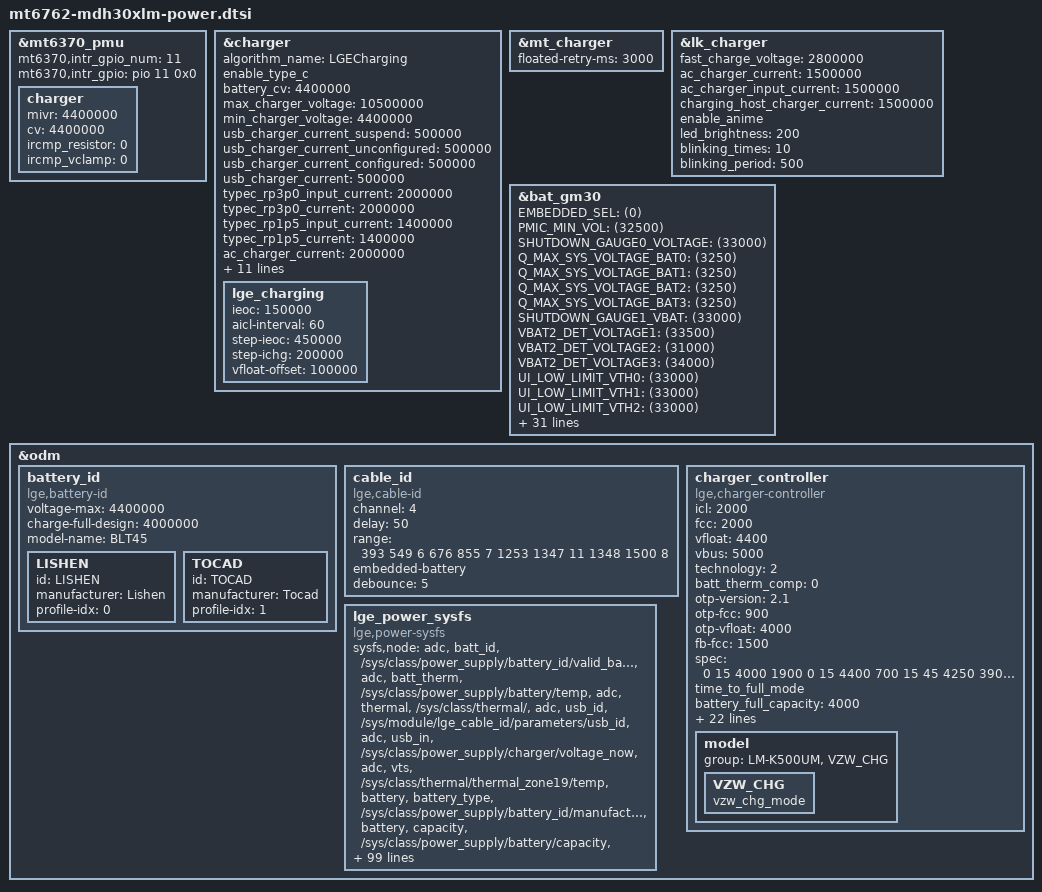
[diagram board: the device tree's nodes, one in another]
/*
 * LG Electronics MT6765 HDK power device tree source
 *
 * Copyright (c) 2018 LG Electronics Co., Ltd.
 *              http://www.lge.com
 *
 */

&mt6370_pmu {
	mt6370,intr_gpio_num = <11>; /* direct defined GPIO num */
	mt6370,intr_gpio = <&pio 11 0x0>;

	charger {
		interrupt-names = "chg_mivr", "chg_aiclmeasi",
			"attachi","ovpctrl_uvp_d_evt", "chg_wdtmri",
			"chg_vbusov","chg_tmri", "chg_treg", "pwr_rdy";
		mivr = <4400000>;	/* uV */
		cv = <4400000>;		/* uA */
		ircmp_resistor = <0>;   /* uohm */
		ircmp_vclamp = <0>;     /* uV */
	};
};

&charger {
	algorithm_name = "LGECharging";

	enable_type_c;

	/* common */
	battery_cv = <4400000>;
	max_charger_voltage = <10500000>;
	min_charger_voltage = <4400000>;

	/* charging current */
	usb_charger_current_suspend = <500000>;
	usb_charger_current_unconfigured = <500000>;
	usb_charger_current_configured = <500000>;
	usb_charger_current = <500000>;
	typec_rp3p0_input_current = <2000000>;
	typec_rp3p0_current = <2000000>;
	typec_rp1p5_input_current = <1400000>;
	typec_rp1p5_current = <1400000>;
	ac_charger_current = <2000000>;
	ac_charger_input_current = <2000000>;
	non_std_ac_charger_current = <500000>;
	charging_host_charger_current = <1500000>;
	apple_1_0a_charger_current = <1000000>;
	apple_2_1a_charger_current = <1000000>;
	ta_ac_charger_current = <2000000>;
	pd_charger_current = <2000000>;

	/* PE 2.0 */
	pe20_ichg_level_threshold = <500000>; /* uA */
	ta_start_battery_soc = <0>;
	ta_stop_battery_soc = <97>;

	/* cable measurement impedance */
	vbat_cable_imp_threshold = <3000000>; /* uV */

	/* LGE Charging Algorithm */
	lge_charging {
		ieoc = <150000>;
		aicl-interval = <60>;

		step-ieoc = <450000>;
		step-ichg = <200000>;
		vfloat-offset = <100000>;
	};
};

&mt_charger {
	floated-retry-ms = <3000>; /* 3000 ms */
};

&lk_charger {
	fast_charge_voltage = <2800000>;
	ac_charger_current = <1500000>;
	ac_charger_input_current = <1500000>;
	charging_host_charger_current = <1500000>;

	enable_anime;
	led_brightness = <200>;
	blinking_times = <10>;
	blinking_period = <500>;
};

&bat_gm30 {
	/*	Configures whether using embedded battery or not.*/
	EMBEDDED_SEL = <(0)>;

	/*
	 * Below setting is cut off 3.3 parameter.
	 * If use cutoff 3.4V, use MTK original parameter
	 */
	/*	vboot voltage for gauge 0%.*/
	PMIC_MIN_VOL = <(32500)>;
	/*	shutdown gauge 0% voltage*/
	SHUTDOWN_GAUGE0_VOLTAGE = <(33000)>;
	/*	System shut down voltage.*/
	Q_MAX_SYS_VOLTAGE_BAT0 = <(3250)>;
	/*	System shut down voltage.*/
	Q_MAX_SYS_VOLTAGE_BAT1 = <(3250)>;
	/*	System shut down voltage.*/
	Q_MAX_SYS_VOLTAGE_BAT2 = <(3250)>;
	/*	System shut down voltage.*/
	Q_MAX_SYS_VOLTAGE_BAT3 = <(3250)>;
	/* no used. Ignore. Just for align with shutdown condition 3.3v */
	SHUTDOWN_GAUGE1_VBAT = <(33000)>;
	/* Related to low voltage tracking */
	VBAT2_DET_VOLTAGE1 = <(33500)>;
	VBAT2_DET_VOLTAGE2 = <(31000)>;
	VBAT2_DET_VOLTAGE3 = <(34000)>;
	/* cut off scenario. below setting means that 2% shutdown with 3.3v. */
	UI_LOW_LIMIT_VTH0 = <(33000)>;
	UI_LOW_LIMIT_VTH1 = <(33000)>;
	UI_LOW_LIMIT_VTH2 = <(33000)>;
	UI_LOW_LIMIT_VTH3 = <(33000)>;
	UI_LOW_LIMIT_VTH4 = <(33000)>;

	g_Q_MAX_SYS_VOLTAGE = <3250 3250 3250 3250>;
	g_PMIC_MIN_VOL = <32500 32500 32500 32500
			32500 32500 32500 32500
			32500 32500 32500 32500
			31200 31200 31200 31200
			30000 30000 30000 30000
			30000 30000 30000 30000
			30000 30000 30000 30000
			30000 30000 30000 30000
			30000 30000 30000 30000
			30000 30000 30000 30000>;

	g_QMAX_SYS_VOL = <32500 32500 32500 32500
			32500 32500 32500 32500
			32500 32500 32500 32500
			31900 31900 31900 31900
			31800 31800 31800 31800
			32500 32500 32500 32500
			32500 32500 32500 32500
			32500 32500 32500 32500
			32500 32500 32500 32500
			32500 32500 32500 32500>;
	/*
	 * Above setting value is cut off 3.3 parameter.
	 * If use cutoff 3.4V, use MTK original parameter
	 */

	/*      Pseudo 100% percentage at T0.*/
	g_FG_PSEUDO100_T0 = <(95)>;
	/*      Pseudo 100% percentage at T1.*/
	g_FG_PSEUDO100_T1 = <(95)>;
	/*      Pseudo 100% percentage at T2.*/
	g_FG_PSEUDO100_T2 = <(95)>;
	/*      Pseudo 100% percentage at T3.*/
	g_FG_PSEUDO100_T3 = <(95)>;

	PSEUDO1_SEL = <(0)>;

	g_FG_PSEUDO1 = <1  1  1  1
			1  1  1  1
			1  1  1  1
			1  1  1  1
			1  1  1  1
			1  1  1  1
			1  1  1  1
			1  1  1  1
			1  1  1  1
			1  1  1  1>;

	DIFFERENCE_FULLOCV_ITH = <(220)>;
	DIFFERENCE_VOLTAGE_UPDATE = <(-1)>;
	AGING1_UPDATE_SOC = <(10)>;
	AGING1_LOAD_SOC = <(50)>;
	AGING_TEMP_DIFF = <(15)>;
	AGING_TEMP_LOW_LIMIT = <(15)>;
	AGING_TEMP_HIGH_LIMIT = <(45)>;
	ZCV_SUSPEND_TIME = <(9)>;
	SLEEP_CURRENT_AVG = <(500)>; /*0.1mA*/

	CAR_TUNE_VALUE = <(100)>;
	HWOCV_OLDOCV_DIFF_CHR = <(2000)>;
	SWOCV_OLDOCV_DIFF_CHR = <(2000)>;
	VIR_OLDOCV_DIFF_EMB = <(2000)>;
	VIR_OLDOCV_DIFF_EMB_LT = <(2000)>;

	POWER_ON_CAR_CHR = <(20)>;
	POWER_ON_CAR_NOCHR = <(-50)>;

	/*The ui_soc will keep 100% until SOC drop X percents after unplugged.*/
	KEEP_100_PERCENT = <(3)>;

#include "../battery_BL-T45.dtsi"
};

&odm {
	/* Battery ID */
	battery_id {
		compatible = "lge,battery-id";

		voltage-max = <4400000>;
		charge-full-design = <4000000>;
		model-name = "BLT45";

		LISHEN {
			id = "LISHEN";
			manufacturer = "Lishen";
			profile-idx = <0>;
		};
		TOCAD {
			id = "TOCAD";
			manufacturer = "Tocad";
			profile-idx = <1>;
		};
	};

	/* Cable ID */
	cable_id {
		compatible = "lge,cable-id";

		channel = <4>;
		delay = <50>;

		/*
		 * Pull-up : 1.8V 150k (1%)
		 * Pull-down : 680k (1%)
		 * ID : 56k (20%), 130k (20%), 910k (20%)
		 * ADC Accuracy : +-10mV
		 */
		range = <
		/*	min 	max 	type	*/
			393	549	6	/* 6: LT_CABLE_56K */
			676	855	7	/* 7: LT_CABLE_130K */
			1253	1347	11	/* 11: LT_CABLE_910K */
			1348	1500	8	/* 8: USB_CABLE_400MA */
		>;

		embedded-battery;
		debounce = <5>;
	};

	/* Charger Controller */
	charger_controller {
		compatible = "lge,charger-controller";

		/* base information */
		icl = <2000>;
		fcc = <2000>;
		vfloat = <4400>;
		vbus = <5000>;
		technology = <2>;
		batt_therm_comp = <0>;

		/* otp */
		otp-version = "2.1";
		otp-fcc = <900>;
		otp-vfloat = <4000>;

		/* restricted charging */
		fb-fcc = <1500>;

		/* spec */
		spec = <
			 0 15 4000 1900	/* 0.5C */
			 0 15 4400  700	/* 0.2C */
			15 45 4250 3900	/* 1.0C */
			15 45 4400 2300	/* 0.6C */
			45 60 4100 1900	/* 0.5C */
		>;

		/* time to full */
		time_to_full_mode;
		battery_full_capacity = <4000>;
		sdp_current = <500>;
		dcp_current = <2000>;
		pep_current = <2200>;
		non_std_current = <500>;
		report_ttf_comp = <0>;
		sdp_comp = <(-2)>;
		dcp_comp = <0>;
		pep_comp = <0>;
		pd_comp = <0>;
		cdp_comp = <0>;
		non_std_comp = <(-2)>;
		min_comp = <0>;
			/*lgc tocad atl byd lishen*/
		batt_comp = <0 (4) 0 0 0>;
			/* current soc */
		cc_data = <2000 0>;
			/* current soc time */
		cv_data = <
			1789	846	1909
			1765	851	1869
			1720	856	1829
			1676	861	1779
			1626	866	1738
			1584	871	1688
			1533	876	1648
			1494	881	1598
			1449	886	1548
			1401	891	1498
			1358	896	1448
			1315	901	1388
			1268	906	1337
			1223	911	1277
			1178	916	1217
			1140	921	1157
			1092	926	1097
			1056	931	1037
			1017	936	966
			970	941	896
			930	946	826
			890	951	756
			851	956	686
			818	961	605
			778	966	525
			743	971	445
			707	977	365
			677	982	265
			638	988	194
			612	991	144
			594	993	94
			577	996	0
			546	1000	0
		>;

		/* game */
		game-fcc = <700>;

		game-light-fcc = <700>;
		game-light-load = <80>;
		game-light-sec = <100>;

		game-lowbatt-fcc = <700>;
		game-lowbatt-soc = <15>;

		/* model */
		model {
			group =
			/* model name, setting */
			"LM-K500UM", "VZW_CHG";

			VZW_CHG {
				/* vzw charge notification */
				vzw_chg_mode;
			};
		};
	};

	/* Unified Power Sysfs */
	lge_power_sysfs {
		compatible = "lge,power-sysfs";
		sysfs,node =
			/* adc group */
			"adc", "batt_id", "/sys/class/power_supply/battery_id/valid_batt_id",
			"adc", "batt_therm", "/sys/class/power_supply/battery/temp",
			"adc", "thermal", "/sys/class/thermal/",
			"adc", "usb_id", "/sys/module/lge_cable_id/parameters/usb_id",
			"adc", "usb_in", "/sys/class/power_supply/charger/voltage_now",
			"adc", "vts", "/sys/class/thermal/thermal_zone19/temp",
			/* battery group */
			"battery", "battery_type", "/sys/class/power_supply/battery_id/manufacturer",
			"battery", "capacity", "/sys/class/power_supply/battery/capacity",
			"battery", "cycle", "/sys/class/power_supply/battery/battery_cycle",
			"battery", "raw_capacity", "/sys/class/power_supply/battery/raw_capacity",
			"battery", "ttf_capacity", "/sys/class/power_supply/battery/ttf_capacity",
			"battery", "health", "/sys/class/power_supply/battery/health",
			"battery", "present", "/sys/class/power_supply/battery/present",
			"battery", "pseudo_batt", "/sys/module/pseudo_power_supply/parameters/pseudo_batt",
			"battery", "temp", "/sys/class/power_supply/battery/temp",
			"battery", "valid_batt_id", "/sys/class/power_supply/battery_id/valid_batt_id",
			"battery", "check_batt_id_for_aat", "/sys/class/power_supply/battery_id/check_batt_id_for_aat",
			"battery", "voltage_now", "/sys/class/power_supply/battery/voltage_now",
			"battery", "status", "/sys/class/power_supply/battery/status",
			"battery", "time_to_full_now", "/sys/class/power_supply/charger_controller/time_to_full_now",
			"battery", "charge_full", "/sys/class/power_supply/battery/charge_full",
			"battery", "charge_full_design", "/sys/class/power_supply/battery/charge_full_design",
			"battery", "charge_counter", "/sys/class/power_supply/battery/charge_counter",
			"battery", "battery_age", "/sys/class/power_supply/battery/battery_age",
			"battery", "battery_age_level", "/sys/class/power_supply/battery/battery_age_level",
			"battery", "condition", "/sys/class/power_supply/battery/battery_condition",
			"battery", "vzw_chg", "/sys/class/power_supply/charger_controller/vzw_chg",
			/* charger group */
			"charger", "ac_online", "/sys/class/power_supply/ac/online",
			"charger", "usb_online", "/sys/class/power_supply/usb/online",
			"charger", "present", "/sys/class/power_supply/charger/online",
			"charger", "ibat_current", "/sys/class/power_supply/battery/current_now",
			"charger", "ichg_current", "/sys/class/power_supply/usb/current_max",
			"charger", "charging_enabled", "/sys/class/power_supply/charger_controller/charging_enabled",
			"charger", "restricted_charging", "/sys/module/charger_controller/parameters/restricted_charging",
			"charger", "store_demo_enabled", "/sys/class/power_supply/charger_controller/store_demo_enabled",
			"charger", "fastchg", "/sys/class/power_supply/charger/fastchg",
			"charger", "fastchg_support", "/sys/class/power_supply/charger/fastchg_support",
			"charger", "incompatible", "/sys/class/power_supply/charger/incompatible_chg",
			"charger", "pseudo_hvdcp", "/sys/module/pseudo_power_supply/parameters/hvdcp_mode",
			"charger", "chgstep", "/sys/module/charger_controller/parameters/chgstep",
			"charger", "chgtype", "/sys/module/charger_controller/parameters/chgtype",
			/* lcd group */
			"lcd", "brightness", "/sys/class/leds/lcd-backlight/brightness",
			"lcd", "max_brightness", "/sys/class/leds/lcd-backlight/max_brightness",
			/* key led group */
			"key_led", "red_brightness", "/sys/class/leds/red/brightness",
			"key_led", "setting", "/sys/class/leds/red/pattern_id",
			/* cpu group */
			"cpu", "game_mode", "/proc/ppm/policy/auto_game_limit",
			/* gpu group */
			/* platform group */
			/* perf service feature group */
			/* testmode group */
			"testmode", "batt_id", "/sys/class/power_supply/battery_id/batt_id",
			"testmode", "battexist", "/sys/class/power_supply/battery/present",
			"testmode", "charge", "/sys/module/charger_controller/parameters/atcmd_charge",
			"testmode", "chcomp", "/sys/module/charger_controller/parameters/atcmd_chcomp",
			"testmode", "chgmodeoff", "/sys/module/charger_controller/parameters/atcmd_chgmodeoff",
			"testmode", "current_max", "/sys/class/power_supply/usb/current_max",
			"testmode", "current_now", "/sys/class/power_supply/battery/current_now",
			"testmode", "fuelval", "/sys/class/power_supply/battery/capacity",
			"testmode", "temp", "/sys/module/charger_controller/parameters/atcmd_batmp",
			"testmode", "usb_id", "/sys/module/lge_cable_id/parameters/atcmd_usb_id",
			"testmode", "valid_batt_id", "/sys/class/power_supply/battery_id/check_batt_id_for_aat",
			"testmode", "voltage_now", "/sys/class/power_supply/battery/voltage_now";
	};
};
